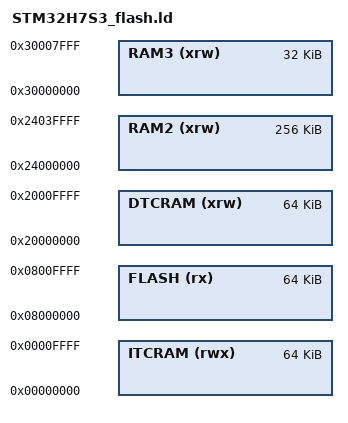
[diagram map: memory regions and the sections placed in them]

MEMORY
{
  FLASH (rx) :    ORIGIN = 0x08000000, LENGTH = 64K

  ITCRAM (rwx) :  ORIGIN = 0x00000000, LENGTH = 64K
  DTCRAM (xrw) :  ORIGIN = 0x20000000, LENGTH = 64K
  RAM2 (xrw) :    ORIGIN = 0x24000000, LENGTH = 256K
  RAM3 (xrw) :    ORIGIN = 0x30000000, LENGTH = 32K
}

REGION_ALIAS("TEXT", FLASH);
REGION_ALIAS("RAM", RAM2);  /* DMA capable RAM */

INCLUDE armm_default_flash.ld

